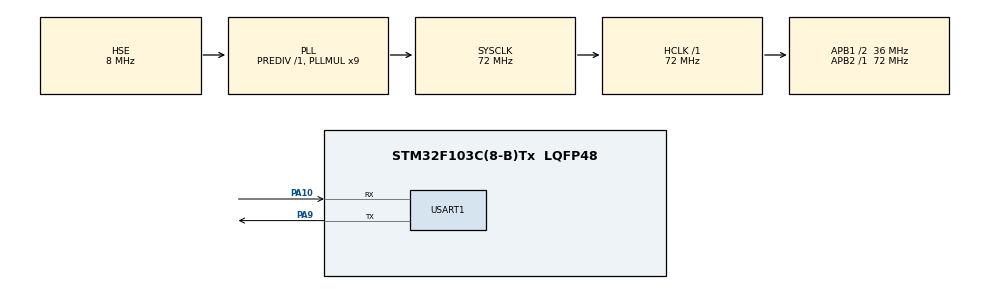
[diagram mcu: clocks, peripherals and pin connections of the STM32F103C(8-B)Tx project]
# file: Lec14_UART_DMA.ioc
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Dma.Request0=USART1_RX
Dma.USART1_RX.0.Direction=DMA_PERIPH_TO_MEMORY
Dma.USART1_RX.0.Instance=DMA1_Channel5
Dma.USART1_RX.0.MemDataAlignment=DMA_MDATAALIGN_BYTE
Dma.USART1_RX.0.MemInc=DMA_MINC_ENABLE
Dma.USART1_RX.0.Mode=DMA_CIRCULAR
Dma.USART1_RX.0.PeriphDataAlignment=DMA_PDATAALIGN_BYTE
Dma.USART1_RX.0.PeriphInc=DMA_PINC_DISABLE
Dma.USART1_RX.0.Priority=DMA_PRIORITY_LOW
Mcu.Family=STM32F1
Mcu.Name=STM32F103C(8-B)Tx
Mcu.Package=LQFP48
NVIC.DMA1_Channel5_IRQn=true\:0\:0\:false\:false\:true\:false\:true\:true
NVIC.PriorityGroup=NVIC_PRIORITYGROUP_4
NVIC.USART1_IRQn=true\:1\:0\:true\:false\:true\:true\:true\:true
PA10.Mode=Asynchronous
PA10.Signal=USART1_RX
PA13.Mode=Serial_Wire
PA13.Signal=SYS_JTMS-SWDIO
PA14.Mode=Serial_Wire
PA14.Signal=SYS_JTCK-SWCLK
PA9.Mode=Asynchronous
PA9.Signal=USART1_TX
PD0-OSC_IN.Mode=HSE-External-Oscillator
PD0-OSC_IN.Signal=RCC_OSC_IN
PD1-OSC_OUT.Mode=HSE-External-Oscillator
PD1-OSC_OUT.Signal=RCC_OSC_OUT
ProjectManager.HeapSize=0x200
ProjectManager.StackSize=0x400
ProjectManager.TargetToolchain=STM32CubeIDE
RCC.AHBFreq_Value=72000000
RCC.APB1CLKDivider=RCC_HCLK_DIV2
RCC.APB1Freq_Value=36000000
RCC.APB1TimFreq_Value=72000000
RCC.APB2Freq_Value=72000000
RCC.APB2TimFreq_Value=72000000
RCC.HCLKFreq_Value=72000000
RCC.PLLMUL=RCC_PLL_MUL9
RCC.PLLSourceVirtual=RCC_PLLSOURCE_HSE
RCC.SYSCLKFreq_VALUE=72000000
RCC.SYSCLKSource=RCC_SYSCLKSOURCE_PLLCLK
RCC.USBFreq_Value=72000000
USART1.VirtualMode=VM_ASYNC
board=custom

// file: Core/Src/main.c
/* USER CODE BEGIN Header */
/**
 ******************************************************************************
 * @file           : main.c
 * @brief          : Main program body
 ******************************************************************************
 * @attention
 *
 * Copyright (c) 2024 STMicroelectronics.
 * All rights reserved.
 *
 * This software is licensed under terms that can be found in the LICENSE file
 * in the root directory of this software component.
 * If no LICENSE file comes with this software, it is provided AS-IS.
 *
 ******************************************************************************
 */
/* USER CODE END Header */
#include "main.h"

UART_HandleTypeDef huart1;
DMA_HandleTypeDef hdma_usart1_rx;

/* USER CODE BEGIN PV */

//define the uart used
UART_HandleTypeDef huart1;

//function declaration for the UART module to be used in interrupt mode
void on_data_received(UART_HandleTypeDef *config_it);

//function declaration
void RxEvent(UART_HandleTypeDef *huart, uint16_t length);

//string is set as volatile because it will be used in interrupt mode
//variable for the string to store the name
volatile char str[100];

//variable for the index in the string
volatile uint8_t str_index = 0;

//variable to store the received byte to determine if it is Enter button or not
volatile char ByteReceived;

/* USER CODE END PV */

void SystemClock_Config(void);
static void MX_GPIO_Init(void);
static void MX_DMA_Init(void);
static void MX_USART1_UART_Init(void);

int main(void) {

	/* USER CODE BEGIN 1 */

	//enable the clock for Port C
	__HAL_RCC_GPIOC_CLK_ENABLE();
	/* USER CODE END 1 */

	/* MCU Configuration--------------------------------------------------------*/

	/* Reset of all peripherals, Initializes the Flash interface and the Systick. */
	HAL_Init();

	/* Configure the system clock */
	SystemClock_Config();

	/* Initialize all configured peripherals */
	MX_GPIO_Init();
	MX_DMA_Init();
	MX_USART1_UART_Init();
	/* USER CODE BEGIN 2 */

	//register callback for the UART module
	//HAL_UART_RegisterCallback(&huart1, HAL_UART_RX_COMPLETE_CB_ID,on_data_received);

	//the RxEvent pointer is pointing to the RxEvnet (the function (function callback) i created)
	//so once it is triggered, it points to the function -> execute this function -> linked together
	huart1.RxEventCallback = RxEvent;

	//asking the user to enter his name
	HAL_UART_Transmit(&huart1, (uint8_t*) "Enter your name\r\n", 18, 100);

	//enable the Receive mode in interrupt mode to initialize the interrupt once data is received
	//data will be received in the string str and it will receive only one byte
	HAL_UARTEx_ReceiveToIdle_DMA(&huart1, (uint8_t*) &str, 1);

	//set pin 13 on port C as output (connected to LED on the board)
	GPIO_InitTypeDef PC13 = { .Pin = GPIO_PIN_13, .Mode = GPIO_MODE_OUTPUT_PP,
			.Speed = GPIO_SPEED_FREQ_HIGH,

	};

	//initialize PIN 13 on PORT C
	HAL_GPIO_Init(GPIOC, &PC13);

	/* USER CODE END 2 */

	/* Infinite loop */
	/* USER CODE BEGIN WHILE */
	while (1) //on the while loop pin is toggled every 500 ms and when data is received interrupt is enabled
	{

		//toggle the pin
		HAL_GPIO_TogglePin(GPIOC, GPIO_PIN_13);

		//delay for 500 ms
		HAL_Delay(500);

		/* USER CODE END WHILE */

	}
}

void SystemClock_Config(void) {
	RCC_OscInitTypeDef RCC_OscInitStruct = { 0 };
	RCC_ClkInitTypeDef RCC_ClkInitStruct = { 0 };

	/** Initializes the RCC Oscillators according to the specified parameters
	 * in the RCC_OscInitTypeDef structure.
	 */
	RCC_OscInitStruct.OscillatorType = RCC_OSCILLATORTYPE_HSE;
	RCC_OscInitStruct.HSEState = RCC_HSE_ON;
	RCC_OscInitStruct.HSEPredivValue = RCC_HSE_PREDIV_DIV1;
	RCC_OscInitStruct.HSIState = RCC_HSI_ON;
	RCC_OscInitStruct.PLL.PLLState = RCC_PLL_ON;
	RCC_OscInitStruct.PLL.PLLSource = RCC_PLLSOURCE_HSE;
	RCC_OscInitStruct.PLL.PLLMUL = RCC_PLL_MUL9;
	if (HAL_RCC_OscConfig(&RCC_OscInitStruct) != HAL_OK) {
		Error_Handler();
	}

	/** Initializes the CPU, AHB and APB buses clocks
	 */
	RCC_ClkInitStruct.ClockType = RCC_CLOCKTYPE_HCLK | RCC_CLOCKTYPE_SYSCLK
			| RCC_CLOCKTYPE_PCLK1 | RCC_CLOCKTYPE_PCLK2;
	RCC_ClkInitStruct.SYSCLKSource = RCC_SYSCLKSOURCE_PLLCLK;
	RCC_ClkInitStruct.AHBCLKDivider = RCC_SYSCLK_DIV1;
	RCC_ClkInitStruct.APB1CLKDivider = RCC_HCLK_DIV2;
	RCC_ClkInitStruct.APB2CLKDivider = RCC_HCLK_DIV1;

	if (HAL_RCC_ClockConfig(&RCC_ClkInitStruct, FLASH_LATENCY_2) != HAL_OK) {
		Error_Handler();
	}
}

static void MX_USART1_UART_Init(void) {

	huart1.Instance = USART1;
	huart1.Init.BaudRate = 115200;
	huart1.Init.WordLength = UART_WORDLENGTH_8B;
	huart1.Init.StopBits = UART_STOPBITS_1;
	huart1.Init.Parity = UART_PARITY_NONE;
	huart1.Init.Mode = UART_MODE_TX_RX;
	huart1.Init.HwFlowCtl = UART_HWCONTROL_NONE;
	huart1.Init.OverSampling = UART_OVERSAMPLING_16;
	if (HAL_UART_Init(&huart1) != HAL_OK) {
		Error_Handler();
	}

}

static void MX_DMA_Init(void) {

	/* DMA controller clock enable */
	__HAL_RCC_DMA1_CLK_ENABLE();

	/* DMA interrupt init */
	/* DMA1_Channel5_IRQn interrupt configuration */
	HAL_NVIC_SetPriority(DMA1_Channel5_IRQn, 0, 0);
	HAL_NVIC_EnableIRQ(DMA1_Channel5_IRQn);

}

static void MX_GPIO_Init(void) {

	/* GPIO Ports Clock Enable */
	__HAL_RCC_GPIOD_CLK_ENABLE();
	__HAL_RCC_GPIOA_CLK_ENABLE();

}

/* USER CODE BEGIN 4 */

//write the interrupt function handler
void on_data_received(UART_HandleTypeDef *config_it) {

	//when the enter button is pressed -> display the entered name
	if (ByteReceived == '\r' || ByteReceived == '\n') {

		//display the contents of the str string
		HAL_UART_Transmit(&huart1, (uint8_t*) "\r\nYour name is: ", 16, 100);
		HAL_UART_Transmit(&huart1, (uint8_t*) str, str_index, 100);
		HAL_UART_Transmit(&huart1, (uint8_t*) "\r\n", 2, 100);

		// Reset the index for the next input
		str_index = 0;

		// ask the user to enter the name again
		HAL_UART_Transmit(&huart1, (uint8_t*) "Enter your name: ", 17, 100);
	}

	//another button is pressed -> store the character into the string of the name
	else {
		//store received byte in the string
		str[str_index] = ByteReceived;

		//increment the string index by 1
		str_index++;
	}

	//wait for another data to be received again
	HAL_UART_Receive_IT(&huart1, (uint8_t*) &ByteReceived, 1);

}
;

//function definition
//this function is executed once the stream of data is sent and nothing is received (IDLE)
//the data stream is saved into the string
void RxEvent(UART_HandleTypeDef *huart, uint16_t length) {

	//display the name
	HAL_UART_Transmit(&huart1, (uint8_t*) "\r\nYour name is: ", 16, 100);

	//the length variable is used in this function
	//because it is returned from the string length
	HAL_UART_Transmit(&huart1, (uint8_t*) str, length, 100);

}

/* USER CODE END 4 */

void Error_Handler(void) {
	__disable_irq();
	while (1) {
	}
}
